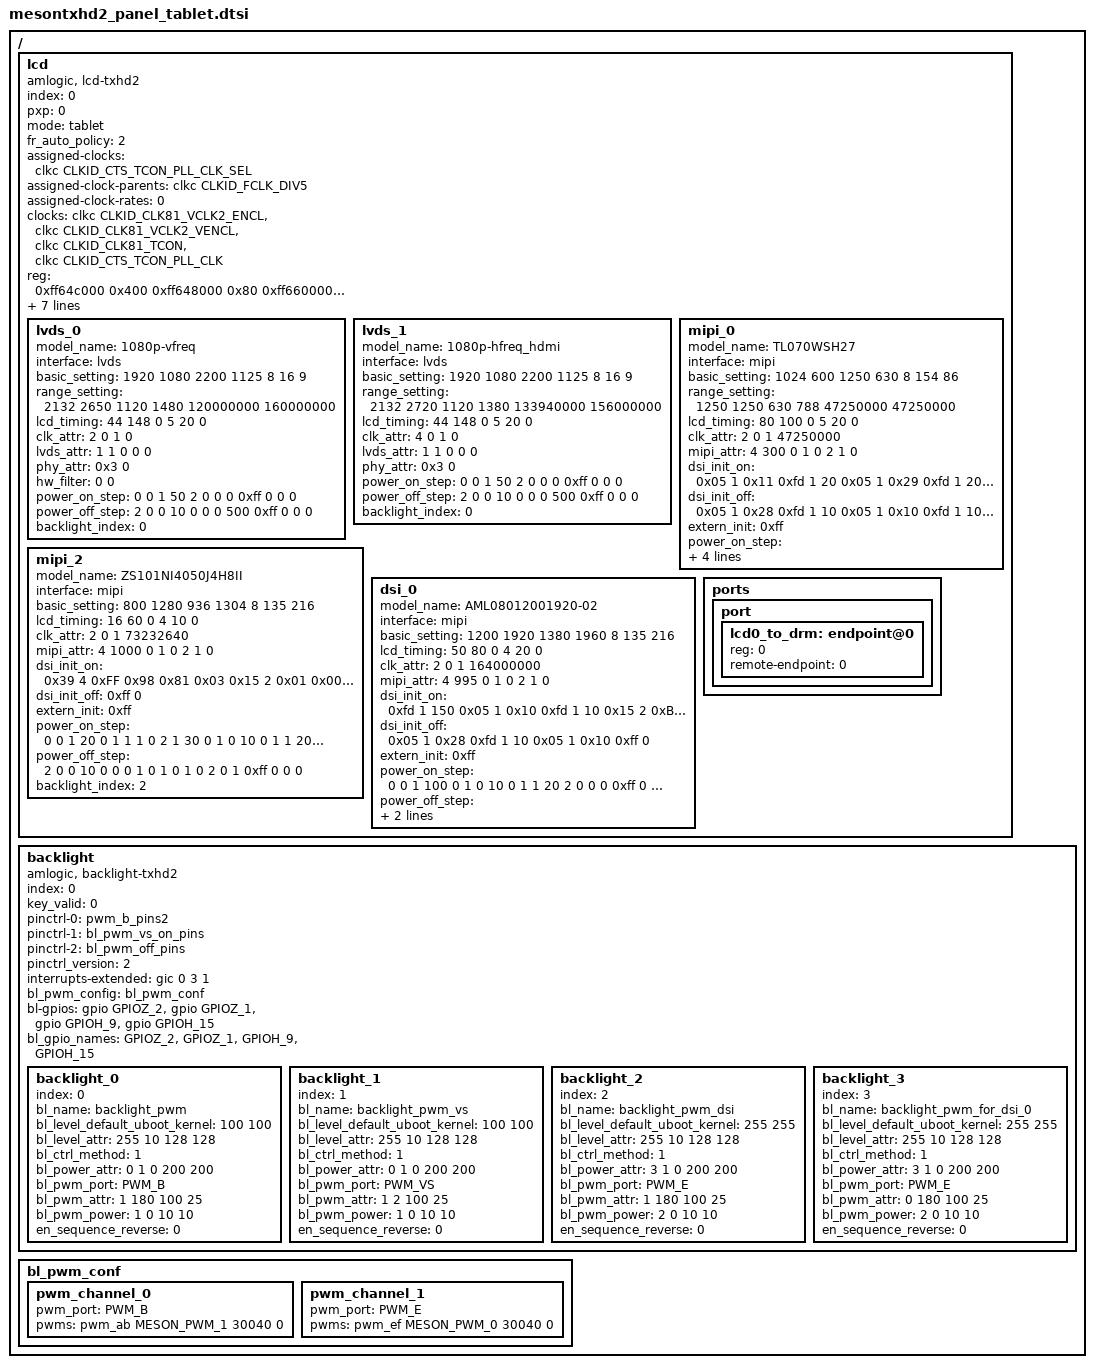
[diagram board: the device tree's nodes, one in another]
// SPDX-License-Identifier: (GPL-2.0+ OR MIT)
/*
 * Copyright (c) 2019 Amlogic, Inc. All rights reserved.
 */

/ {
	lcd:lcd {
		compatible = "amlogic, lcd-txhd2";
		status = "okay";
		index = <0>;
		pxp = <0>;
		mode = "tablet";
		fr_auto_policy = <2>; /* 0=disable, 1=enable */
		assigned-clocks = <&clkc CLKID_CTS_TCON_PLL_CLK_SEL>;
		assigned-clock-parents = <&clkc CLKID_FCLK_DIV5>;
		assigned-clock-rates = <0>;
		clocks = <&clkc CLKID_CLK81_VCLK2_ENCL>, <&clkc CLKID_CLK81_VCLK2_VENCL>,
			 <&clkc CLKID_CLK81_TCON>, <&clkc CLKID_CTS_TCON_PLL_CLK>;
		clock-names = "encl_top_gate", "encl_int_gate", "tcon_gate", "clk_tcon";
		reg = <0xff64c000 0x400    /* dsi_host */
			0xff648000 0x80    /* dsi_phy */
			0xff660000 0xd000  /* tcon */
			0xff634400 0x300   /* periphs */
			0xffd01000 0xa0    /* reset */
			0xff648000 0x100>; /* combo_dphy */
		interrupts = <0 3 1
			0 88 1>;
		interrupt-names = "vsync","tcon";

		lcd_cpu-gpios = <&gpio GPIOZ_3  GPIO_ACTIVE_HIGH
				 &gpio GPIOH_14 GPIO_ACTIVE_HIGH
				 &gpio GPIOH_10 GPIO_ACTIVE_HIGH>;
		lcd_cpu_gpio_names = "GPIOZ_3", "GPIOH_14", "GPIOH_10";

		config_check_glb = <1>;
		display_timing_req_min = <1  /*alert_level: 0:disable, 1:warning, 2:fatal error*/
			45   /*hsw+hbp*/
			0    /*hfp, 0 for no need*/
			20   /*vsw+vbp*/
			15>; /*vfp*/

		lvds_0{
			model_name = "1080p-vfreq";
			interface = "lvds"; /*lcd_interface(lvds, vbyone)*/
			basic_setting = <
				1920 1080 /*h_active, v_active*/
				2200 1125 /*h_period, v_period*/
				8      /*lcd_bits */
				16 9>; /*screen_widht, screen_height*/
			range_setting = <
				2132 2650  /*h_period_min,max*/
				1120 1480  /*v_period_min,max*/
				120000000 160000000>; /*pclk_min,max*/
			lcd_timing = <
				44 148 0  /*hs_width, hs_bp, hs_pol*/
				5  20 0>; /*vs_width, vs_bp, vs_pol*/
			clk_attr = <
				2 /*fr_adj_type: 0=clk, 1=htotal, 2=vtotal, 3=auto, 4=hdmi */
				0 /*clk_ss: [0:7]:level, [8:11]:freq, [12:15]: mode*/
				1 /*clk_auto_generate*/
				0>; /*pixel_clk(unit in Hz)*/
			lvds_attr = <
				1  /*lvds_repack*/
				1  /*dual_port*/
				0  /*pn_swap*/
				0  /*port_swap*/
				0>; /*lane_reverse*/
			phy_attr=<0x3 0>; /*vswing_level, preem_level*/
			hw_filter=<0 0>;  /* filter_time, filter_cnt*/

			/* power step: type, index, value, delay(ms) */
			power_on_step = <
				0 0 1 50   /*panel power*/
				2 0 0 0   /*signal enable*/
				0xff 0 0 0>; /*ending*/
			power_off_step = <
				2 0 0 10  /*signal disable*/
				0 0 0 500   /*panel power*/
				0xff 0 0 0>; /*ending*/
			backlight_index = <0>;
		};
		lvds_1{
			model_name = "1080p-hfreq_hdmi";
			interface = "lvds"; /*lcd_interface(lvds, vbyone)*/
			basic_setting = <
				1920 1080 /*h_active, v_active*/
				2200 1125 /*h_period, v_period*/
				8      /*lcd_bits*/
				16 9>; /*screen_widht, screen_height*/
			range_setting = <
				2132 2720 /*h_period min, max*/
				1120 1380 /*v_period min, max*/
				133940000 156000000>; /*pclk_min, max*/
			lcd_timing = <
				44 148 0   /*hs_width, hs_bp, hs_pol*/
				5  20  0>; /*vs_width, vs_bp, vs_pol*/
			clk_attr = <
				4 /*fr_adj_type: 0=clk, 1=htotal, 2=vtotal, 3=auto, 4=hdmi */
				0 /*clk_ss_level */
				1 /*clk_auto_generate*/
				0>; /*pixel_clk(unit in Hz)*/
			lvds_attr = <
				1 /*lvds_repack*/
				1 /*dual_port*/
				0 /*pn_swap*/
				0 /*port_swap*/
				0>; /*lane_reverse*/
			phy_attr=<0x3 0>; /*vswing_level, preem_level*/

			/* power step: type, index, value, delay(ms) */
			power_on_step = <
				0 0 1 50   /*panel power*/
				2 0 0 0   /*signal enable*/
				0xff 0 0 0>; /*ending*/
			power_off_step = <
				2 0 0 10  /*signal disable*/
				0 0 0 500   /*panel power*/
				0xff 0 0 0>; /*ending*/
			backlight_index = <0>;
		};

		mipi_0{
			model_name = "TL070WSH27";
			interface = "mipi";
			/*h_active, v_active, h_period, v_period, color_bit, width, height*/
			basic_setting = <1024 600 1250 630 8 154 86>;
			/* h_period(min, max) v_period(min, max) pclk(min, max) */
			range_setting = <1250 1250 630 788 47250000 47250000>;
			/*hs_width, hs_bp, hs_pol, vs_width, vs_bp, vs_pol*/
			lcd_timing = <80 100 0 5 20 0>;
			/* fr_adj_type(0=clk, 1=htotal, 2=vtotal), clk_ss_level, 1, pixel_clk */
			clk_attr = <2 0 1 47250000>; /*pixel_clk(unit in Hz)*/
			/* <lane, bit_rate, /, mode_init(0=video,1=cmd), mode_disp(0=video,1=cmd)*/
			/* video_mode(0=sync_pulse,1=sync_event,2=burst), clk_hs, />*/
			mipi_attr = <4 300 0 1 0 2 1 0>;

			/* dsi_init: data_type, num, data... */
			dsi_init_on = <0x05 1 0x11
					0xfd 1 20     /*delay(ms)*/
					0x05 1 0x29
					0xfd 1 20     /*delay(ms)*/
					0xff 0>; /*ending*/
			dsi_init_off = <0x05 1 0x28
					0xfd 1 10     /*delay(ms)*/
					0x05 1 0x10
					0xfd 1 10     /*delay(ms)*/
					0xff 0>; /*ending*/
			extern_init = <0xff>; /*0xff for invalid*/

			/* power step: type, index, value, delay(ms) */
			power_on_step = <
				0 0 1 100
				0 1 0 10
				0 1 1 20
				2 0 0 0
				0xff 0 0 0>; /*ending*/
			power_off_step = <
				2 0 0 50
				0 1 0 10
				0 0 0 100
				0xff 0 0 0>; /*ending*/
			backlight_index = <2>;
		};

		mipi_2{
			model_name = "ZS101NI4050J4H8II";
			interface = "mipi";
			/*h_active, v_active, h_period, v_period, color_bit, width, height*/
			basic_setting = <800 1280 936 1304 8 135 216>;
			/*hs_width, hs_bp, hs_pol, vs_width, vs_bp, vs_pol*/
			lcd_timing = <16 60 0 4 10 0>;
			/* fr_adj_type(0=clk, 1=htotal, 2=vtotal), clk_ss_level, 1, pixel_clk */
			clk_attr = <2 0 1 73232640>;
			/* <lane, bit_rate, /, mode_init(0=video,1=cmd), mode_disp(0=video,1=cmd)*/
			/* video_mode(0=sync_pulse,1=sync_event,2=burst), clk_hs, />*/
			mipi_attr = <4 1000 0 1 0 2 1 0>;

			/* dsi_init: data_type, num, data... */
			dsi_init_on = <
				0x39 4 0xFF 0x98 0x81 0x03
				0x15 2 0x01 0x00 0x15 2 0x02 0x00 0x15 2 0x03 0x53 0x15 2 0x04 0x53
				0x15 2 0x05 0x13 0x15 2 0x06 0x04 0x15 2 0x07 0x02 0x15 2 0x08 0x02
				0x15 2 0x09 0x00 0x15 2 0x0a 0x00 0x15 2 0x0b 0x00 0x15 2 0x0c 0x00
				0x15 2 0x0d 0x00 0x15 2 0x0e 0x00 0x15 2 0x0f 0x00 0x15 2 0x10 0x00
				0x15 2 0x11 0x00 0x15 2 0x12 0x00 0x15 2 0x13 0x00 0x15 2 0x14 0x00
				0x15 2 0x15 0x05 0x15 2 0x16 0x05 0x15 2 0x17 0x03 0x15 2 0x18 0x03
				0x15 2 0x19 0x00 0x15 2 0x1a 0x00 0x15 2 0x1b 0x00 0x15 2 0x1c 0x00
				0x15 2 0x1d 0x00 0x15 2 0x1e 0xc0 0x15 2 0x1f 0x00 0x15 2 0x20 0x02
				0x15 2 0x21 0x09 0x15 2 0x22 0x00 0x15 2 0x23 0x00 0x15 2 0x24 0x00
				0x15 2 0x25 0x00 0x15 2 0x26 0x00 0x15 2 0x27 0x00 0x15 2 0x28 0x55
				0x15 2 0x29 0x03 0x15 2 0x2a 0x00 0x15 2 0x2b 0x00 0x15 2 0x2c 0x00
				0x15 2 0x2d 0x00 0x15 2 0x2e 0x00 0x15 2 0x2f 0x00 0x15 2 0x30 0x00
				0x15 2 0x31 0x00 0x15 2 0x32 0x00 0x15 2 0x33 0x00 0x15 2 0x34 0x00
				0x15 2 0x35 0x00 0x15 2 0x36 0x00 0x15 2 0x37 0x00 0x15 2 0x38 0x3C
				0x15 2 0x39 0x00 0x15 2 0x3a 0x00 0x15 2 0x3b 0x00 0x15 2 0x3c 0x00
				0x15 2 0x3d 0x00 0x15 2 0x3e 0x00 0x15 2 0x3f 0x00 0x15 2 0x40 0x00
				0x15 2 0x41 0x00 0x15 2 0x42 0x00 0x15 2 0x43 0x00 0x15 2 0x44 0x00
				0x15 2 0x50 0x01 0x15 2 0x51 0x23 0x15 2 0x52 0x45 0x15 2 0x53 0x67
				0x15 2 0x54 0x89 0x15 2 0x55 0xab 0x15 2 0x56 0x01 0x15 2 0x57 0x23
				0x15 2 0x58 0x45 0x15 2 0x59 0x67 0x15 2 0x5a 0x89 0x15 2 0x5b 0xab
				0x15 2 0x5c 0xcd 0x15 2 0x5d 0xef 0x15 2 0x5e 0x01 0x15 2 0x5f 0x0A
				0x15 2 0x60 0x02 0x15 2 0x61 0x02 0x15 2 0x62 0x08 0x15 2 0x63 0x15
				0x15 2 0x64 0x14 0x15 2 0x65 0x02 0x15 2 0x66 0x11 0x15 2 0x67 0x10
				0x15 2 0x68 0x02 0x15 2 0x69 0x0F 0x15 2 0x6a 0x0E 0x15 2 0x6b 0x02
				0x15 2 0x6c 0x0D 0x15 2 0x6d 0x0C 0x15 2 0x6e 0x06 0x15 2 0x6f 0x02
				0x15 2 0x70 0x02 0x15 2 0x71 0x02 0x15 2 0x72 0x02 0x15 2 0x73 0x02
				0x15 2 0x74 0x02 0x15 2 0x75 0x0A 0x15 2 0x76 0x02 0x15 2 0x77 0x02
				0x15 2 0x78 0x06 0x15 2 0x79 0x15 0x15 2 0x7a 0x14 0x15 2 0x7b 0x02
				0x15 2 0x7c 0x10 0x15 2 0x7d 0x11 0x15 2 0x7e 0x02 0x15 2 0x7f 0x0C
				0x15 2 0x80 0x0D 0x15 2 0x81 0x02 0x15 2 0x82 0x0E 0x15 2 0x83 0x0F
				0x15 2 0x84 0x08 0x15 2 0x85 0x02 0x15 2 0x86 0x02 0x15 2 0x87 0x02
				0x15 2 0x88 0x02 0x15 2 0x89 0x02 0x15 2 0x8A 0x02
				0x39 4 0xFF 0x98 0x81 0x04
				0x15 2 0x3B 0xC0 0x15 2 0x6C 0x15 0x15 2 0x6E 0x30 0x15 2 0x6F 0x33
				0x15 2 0x8D 0x1F 0x15 2 0x3A 0x24 0x15 2 0x35 0x1F 0x15 2 0x87 0xBA
				0x15 2 0x26 0x76 0x15 2 0xB2 0xD1 0x15 2 0xB5 0x07 0x15 2 0x88 0x0B
				0x15 2 0x21 0x30
				0x39 4 0xFF 0x98 0x81 0x01
				0x15 2 0x22 0x0A 0x15 2 0x31 0x09 0x15 2 0x40 0x33 0x15 2 0x42 0x44
				0x15 2 0x53 0x2E 0x15 2 0x55 0x88 0x15 2 0x50 0x95 0x15 2 0x51 0x95
				0x15 2 0x60 0x43 0x15 2 0x2E 0xC8 0x15 2 0xA0 0x0F 0x15 2 0xA1 0x1D
				0x15 2 0xA2 0x2A 0x15 2 0xA3 0x14 0x15 2 0xA4 0x16 0x15 2 0xA5 0x29
				0x15 2 0xA6 0x1D 0x15 2 0xA7 0x1E 0x15 2 0xA8 0x83 0x15 2 0xA9 0x1E
				0x15 2 0xAA 0x2B 0x15 2 0xAB 0x6F 0x15 2 0xAC 0x18 0x15 2 0xAD 0x17
				0x15 2 0xAE 0x4C 0x15 2 0xAF 0x22 0x15 2 0xB0 0x27 0x15 2 0xB1 0x4D
				0x15 2 0xB2 0x5C 0x15 2 0xB3 0x2B 0x15 2 0xC0 0x0F 0x15 2 0xC1 0x1D
				0x15 2 0xC2 0x2A 0x15 2 0xC3 0x14 0x15 2 0xC4 0x16 0x15 2 0xC5 0x29
				0x15 2 0xC6 0x1D 0x15 2 0xC7 0x1E 0x15 2 0xC8 0x83 0x15 2 0xC9 0x1E
				0x15 2 0xCA 0x2B 0x15 2 0xCB 0x6F 0x15 2 0xCC 0x18 0x15 2 0xCD 0x17
				0x15 2 0xCE 0x4C 0x15 2 0xCF 0x22 0x15 2 0xD0 0x27 0x15 2 0xD1 0x4D
				0x15 2 0xD2 0x5C 0x15 2 0xD3 0x2B
				0x39 4 0xFF 0x98 0x81 0x00
				0x15 2 0x35 0x00
				0x05 1 0x11
				0xfd 1 120
				0x05 1 0x29
				0xfd 1 20
				0xff 0>; /*ending*/
			dsi_init_off = <0xff 0>; /*ending*/
			extern_init = <0xff>; /*0xff for invalid*/

			/* power step: type, index, value, delay(ms) */
			power_on_step = <
				0 0 1 20
				0 1 1 1
				0 2 1 30
				0 1 0 10
				0 1 1 20
				2 0 0 0
				0xff 0 0 0>; /*ending*/
			power_off_step = <
				2 0 0 10
				0 0 0 1
				0 1 0 1
				0 2 0 1
				0xff 0 0 0>; /*ending*/
			backlight_index = <2>;
		};
		dsi_0{
			model_name = "AML08012001920-02";
			interface = "mipi";
			/*h_active, v_active, h_period, v_period, color_bit, width, height*/
			basic_setting = <1200 1920 1380 1960 8 135 216>;
			/*hs_width, hs_bp, hs_pol, vs_width, vs_bp, vs_pol*/
			lcd_timing = <50 80 0 4 20 0>;
			/* fr_adj_type(0=clk, 1=htotal, 2=vtotal), clk_ss_level, 1, pixel_clk */
			clk_attr = <2 0 1 164000000>;
			/* <lane, bit_rate, /, mode_init(0=video,1=cmd), mode_disp(0=video,1=cmd)*/
			/* video_mode(0=sync_pulse,1=sync_event,2=burst), clk_hs, />*/
			mipi_attr = <4 995 0 1 0 2 1 0>;
			/* dsi_init: data_type, num, data... */
			dsi_init_on = <
				0xfd 1 150
				0x05 1 0x10
				0xfd 1 10
				0x15 2 0xB0 0x05 0x15 2 0xB3 0x52 0x15 2 0xB0 0x01 0x15 2 0xC8 0x00
				0x15 2 0xC9 0x00 0x15 2 0xCC 0x26 0x15 2 0xCD 0x26 0x15 2 0xDC 0x00
				0x15 2 0xDD 0x00 0x15 2 0xE0 0x26 0x15 2 0xE1 0x26 0x15 2 0xB0 0x03
				0x15 2 0xC3 0x2A 0x15 2 0xE7 0x2A 0x15 2 0xC5 0x2A 0x15 2 0xDE 0x2A
				0x15 2 0xB0 0x00 0x15 2 0xB6 0x03 0x15 2 0xBA 0x87 0x15 2 0xBD 0x78
				0x15 2 0xBF 0x15 0x15 2 0xC0 0x12 0x15 2 0xC2 0x0C 0x15 2 0xC3 0x02
				0x15 2 0xC4 0x0C 0x15 2 0xC5 0x02 0x15 2 0xB0 0x06 0x15 2 0xC0 0xA5
				0x15 2 0xD5 0x20 0x15 2 0xC0 0x00
				0x15 2 0xB0 0x02 /* page2 */
				0x15 2 0xC0 0x00 0x15 2 0xC1 0x02 0x15 2 0xC2 0x06 0x15 2 0xC3 0x16
				0x15 2 0xC4 0x0E 0x15 2 0xC5 0x18 0x15 2 0xC6 0x26 0x15 2 0xC7 0x32
				0x15 2 0xC8 0x3F 0x15 2 0xC9 0x3F 0x15 2 0xCA 0x3F 0x15 2 0xCB 0x3F
				0x15 2 0xCC 0x3D 0x15 2 0xCD 0x2F 0x15 2 0xCE 0x2F 0x15 2 0xCF 0x2F
				0x15 2 0xD0 0x07 0x15 2 0xD2 0x00 0x15 2 0xD3 0x02 0x15 2 0xD4 0x06
				0x15 2 0xD5 0x12 0x15 2 0xD6 0x0A 0x15 2 0xD7 0x14 0x15 2 0xD8 0x22
				0x15 2 0xD9 0x2E 0x15 2 0xDA 0x3D 0x15 2 0xDB 0x3F 0x15 2 0xDC 0x3F
				0x15 2 0xDD 0x3F 0x15 2 0xDE 0x3D 0x15 2 0xDF 0x2F 0x15 2 0xE0 0x2F
				0x15 2 0xE1 0x2F 0x15 2 0xE2 0x07
				0x15 2 0xB0 0x07 /* page7 */
				0x15 2 0xB1 0x00 0x15 2 0xB2 0x19 0x15 2 0xB3 0x31 0x15 2 0xB4 0x5A
				0x15 2 0xB5 0x7C 0x15 2 0xB6 0x9C 0x15 2 0xB7 0xD3 0x15 2 0xB8 0x0E
				0x15 2 0xB9 0x7D 0x15 2 0xBA 0xE0 0x15 2 0xBB 0x7A 0x15 2 0xBC 0xE6
				0x15 2 0xBD 0xE9 0x15 2 0xBE 0x41 0x15 2 0xBF 0x91 0x15 2 0xC0 0xB0
				0x15 2 0xC1 0xCF 0x15 2 0xC2 0xDC 0x15 2 0xC3 0xE9 0x15 2 0xC4 0xEF
				0x15 2 0xC5 0xF5 0x15 2 0xC6 0xFA 0x15 2 0xC7 0xFB 0x15 2 0xC8 0xFC
				0x15 2 0xC9 0x00 0x15 2 0xCA 0x01 0x15 2 0xCB 0x5A 0x15 2 0xCC 0xBF
				0x15 2 0xCD 0xFF 0x15 2 0xCE 0xFF
				0x15 2 0xB0 0x08 /* page8 */
				0x15 2 0xB1 0x00 0x15 2 0xB2 0x19 0x15 2 0xB3 0x31 0x15 2 0xB4 0x5A
				0x15 2 0xB5 0x7C 0x15 2 0xB6 0x9C 0x15 2 0xB7 0xD3 0x15 2 0xB8 0x0E
				0x15 2 0xB9 0x7D 0x15 2 0xBA 0xE0 0x15 2 0xBB 0x7A 0x15 2 0xBC 0xE6
				0x15 2 0xBD 0xE9 0x15 2 0xBE 0x41 0x15 2 0xBF 0x91 0x15 2 0xC0 0xB0
				0x15 2 0xC1 0xCF 0x15 2 0xC2 0xDC 0x15 2 0xC3 0xE9 0x15 2 0xC4 0xEF
				0x15 2 0xC5 0xF5 0x15 2 0xC6 0xFA 0x15 2 0xC7 0xFB 0x15 2 0xC8 0xFC
				0x15 2 0xC9 0x00 0x15 2 0xCA 0x01 0x15 2 0xCB 0x5A 0x15 2 0xCC 0xBF
				0x15 2 0xCD 0xFF 0x15 2 0xCE 0xFF
				0x15 2 0xB0 0x09 /* page9 */
				0x15 2 0xB1 0x00 0x15 2 0xB2 0x19 0x15 2 0xB3 0x31 0x15 2 0xB4 0x5A
				0x15 2 0xB5 0x7C 0x15 2 0xB6 0x9C 0x15 2 0xB7 0xD3 0x15 2 0xB8 0x0E
				0x15 2 0xB9 0x7D 0x15 2 0xBA 0xE0 0x15 2 0xBB 0x7A 0x15 2 0xBC 0xE6
				0x15 2 0xBD 0xE9 0x15 2 0xBE 0x41 0x15 2 0xBF 0x91 0x15 2 0xC0 0xB0
				0x15 2 0xC1 0xCF 0x15 2 0xC2 0xDC 0x15 2 0xC3 0xE9 0x15 2 0xC4 0xEF
				0x15 2 0xC5 0xF5 0x15 2 0xC6 0xFA 0x15 2 0xC7 0xFB 0x15 2 0xC8 0xFC
				0x15 2 0xC9 0x00 0x15 2 0xCA 0x01 0x15 2 0xCB 0x5A 0x15 2 0xCC 0xBF
				0x15 2 0xCD 0xFF 0x15 2 0xCE 0xFF
				0x15 2 0xB0 0x0A /* page10 */
				0x15 2 0xB1 0x00 0x15 2 0xB2 0x19 0x15 2 0xB3 0x31 0x15 2 0xB4 0x5A
				0x15 2 0xB5 0x7C 0x15 2 0xB6 0x9C 0x15 2 0xB7 0xD3 0x15 2 0xB8 0x0E
				0x15 2 0xB9 0x7D 0x15 2 0xBA 0xE0 0x15 2 0xBB 0x7A 0x15 2 0xBC 0xE6
				0x15 2 0xBD 0xE9 0x15 2 0xBE 0x41 0x15 2 0xBF 0x91 0x15 2 0xC0 0xB0
				0x15 2 0xC1 0xCF 0x15 2 0xC2 0xDC 0x15 2 0xC3 0xE9 0x15 2 0xC4 0xEF
				0x15 2 0xC5 0xF5 0x15 2 0xC6 0xFA 0x15 2 0xC7 0xFC 0x15 2 0xC8 0xFC
				0x15 2 0xC9 0x00 0x15 2 0xCA 0x01 0x15 2 0xCB 0x5A 0x15 2 0xCC 0xBF
				0x15 2 0xCD 0xFF 0x15 2 0xCE 0xFF
				0x15 2 0xB0 0x0B /* page11 */
				0x15 2 0xB1 0x00 0x15 2 0xB2 0x19 0x15 2 0xB3 0x31 0x15 2 0xB4 0x5A
				0x15 2 0xB5 0x7C 0x15 2 0xB6 0x9C 0x15 2 0xB7 0xD3 0x15 2 0xB8 0x0E
				0x15 2 0xB9 0x7D 0x15 2 0xBA 0xE0 0x15 2 0xBB 0x7A 0x15 2 0xBC 0xE6
				0x15 2 0xBD 0xE9 0x15 2 0xBE 0x41 0x15 2 0xBF 0x91 0x15 2 0xC0 0xB0
				0x15 2 0xC1 0xCF 0x15 2 0xC2 0xDC 0x15 2 0xC3 0xE9 0x15 2 0xC4 0xEF
				0x15 2 0xC5 0xF5 0x15 2 0xC6 0xFA 0x15 2 0xC7 0xFC 0x15 2 0xC8 0xFC
				0x15 2 0xC9 0x00 0x15 2 0xCA 0x01 0x15 2 0xCB 0x5A 0x15 2 0xCC 0xBF
				0x15 2 0xCD 0xFF 0x15 2 0xCE 0xFF
				0x15 2 0xB0 0x0C /* page12 */
				0x15 2 0xB1 0x00 0x15 2 0xB2 0x19 0x15 2 0xB3 0x31 0x15 2 0xB4 0x5A
				0x15 2 0xB5 0x7C 0x15 2 0xB6 0x9C 0x15 2 0xB7 0xD3 0x15 2 0xB8 0x0E
				0x15 2 0xB9 0x7D 0x15 2 0xBA 0xE0 0x15 2 0xBB 0x7A 0x15 2 0xBC 0xE6
				0x15 2 0xBD 0xE9 0x15 2 0xBE 0x41 0x15 2 0xBF 0x91 0x15 2 0xC0 0xB0
				0x15 2 0xC1 0xCF 0x15 2 0xC2 0xDC 0x15 2 0xC3 0xE9 0x15 2 0xC4 0xEF
				0x15 2 0xC5 0xF5 0x15 2 0xC6 0xFA 0x15 2 0xC7 0xFC 0x15 2 0xC8 0xFC
				0x15 2 0xC9 0x00 0x15 2 0xCA 0x01 0x15 2 0xCB 0x5A 0x15 2 0xCC 0xBF
				0x15 2 0xCD 0xFF 0x15 2 0xCE 0xFF
				0xfd 1 10
				0x05 1 0x11
				0xfd 1 100
				0x05 1 0x29
				0xfd 1 50
				0xff 0>; /*ending*/
			dsi_init_off = <
				0x05 1 0x28
				0xfd 1 10
				0x05 1 0x10
				0xff 0>;
			extern_init = <0xff>; /*0xff for invalid*/

			/* power step: type, index, value, delay(ms) */
			power_on_step = <
				0 0 1 100
				0 1 0 10
				0 1 1 20
				2 0 0 0
				0xff 0 0 0>; /*ending*/
			power_off_step = <
				2 0 0 50
				0 1 0 10
				0 0 0 100
				0xff 0 0 0>; /*ending*/
			backlight_index = <0x3>;
		};
		ports {
			port {
				#address-cells = <1>;
				#size-cells = <0>;
				lcd0_to_drm: endpoint@0 {
					reg = <0>;
					remote-endpoint = <0>;
				};
			};
		};
	};

	backlight{
		compatible = "amlogic, backlight-txhd2";
		status = "okay";
		index = <0>;
		key_valid = <0>;
		pinctrl-names = "pwm_on","pwm_vs_on",
				"pwm_off";
		pinctrl-0 = <&pwm_b_pins2>;
		pinctrl-1 = <&bl_pwm_vs_on_pins>;
		pinctrl-2 = <&bl_pwm_off_pins>;
		pinctrl_version = <2>; /* for uboot */
		interrupts-extended = <&gic 0 3 1>;
		interrupt-names = "vsync";
		bl_pwm_config = <&bl_pwm_conf>;

		/* pwm port: PWM_A, PWM_B, PWM_C, PWM_D, PWM_E, PWM_F, PWM_VS*/
		/* power index:(point gpios_index, 0xff=invalid) */
		/* power value:(0=output low, 1=output high, 2=input) */
		/* power delay:(unit in ms) */
		bl-gpios = <&gpio GPIOZ_2 GPIO_ACTIVE_HIGH
			&gpio GPIOZ_1 GPIO_ACTIVE_HIGH
			&gpio GPIOH_9 GPIO_ACTIVE_HIGH
			&gpio GPIOH_15 GPIO_ACTIVE_HIGH>;
		bl_gpio_names = "GPIOZ_2", "GPIOZ_1", "GPIOH_9", "GPIOH_15";

		backlight_0{
			index = <0>;
			bl_name = "backlight_pwm";
			bl_level_default_uboot_kernel = <100 100>;
			bl_level_attr = <255 10 /*max, min*/
				128 128>; /*mid, mid_mapping*/
			bl_ctrl_method = <1>; /*1=pwm,2=pwm_combo,3=ldim*/
			bl_power_attr = <0 /*en_gpio_index*/
				1 0 /*on_value, off_value*/
				200 200>; /*on_delay(ms), off_delay(ms)*/
			bl_pwm_port = "PWM_B";
			bl_pwm_attr = <1 /*pwm_method(0=negative, 1=positive)*/
				180 /*pwm_freq(pwm:Hz, pwm_vs:multiple of vs)*/
				100 25>; /*duty_max(%), duty_min(%)*/
			bl_pwm_power = <1 0 /*pwm_gpio_index, pwm_gpio_off*/
				10 10>; /*pwm_on_delay(ms), pwm_off_delay(ms)*/
			en_sequence_reverse = <0>; /* 1 for reverse */
		};
		backlight_1{
			index = <1>;
			bl_name = "backlight_pwm_vs";
			bl_level_default_uboot_kernel = <100 100>;
			bl_level_attr = <255 10 /*max, min*/
				128 128>; /*mid, mid_mapping*/
			bl_ctrl_method = <1>; /*1=pwm,2=pwm_combo,3=ldim*/
			bl_power_attr = <0  /*en_gpio_index*/
				1 0 /*on_value, off_value*/
				200 200>; /* on_delay(ms), off_delay(ms)*/
			bl_pwm_port = "PWM_VS";
			bl_pwm_attr = <1 /*pwm_method(0=negative, 1=positive)*/
				2 /*pwm_freq(pwm:Hz, pwm_vs:multiple of vs)*/
				100 25>; /*duty_max(%), duty_min(%)*/
			bl_pwm_power = <1 0 /*pwm_gpio_index, pwm_gpio_off*/
				10 10>; /*pwm_on_delay(ms), pwm_off_delay(ms)*/
			en_sequence_reverse = <0>; /* 1 for reverse */
		};
		backlight_2{
			index = <2>;
			bl_name = "backlight_pwm_dsi";
			bl_level_default_uboot_kernel = <255 255>;
			bl_level_attr = <255 10 /*max, min*/
				128 128>; /*mid, mid_mapping*/
			bl_ctrl_method = <1>; /*1=pwm,2=pwm_combo,3=ldim*/
			bl_power_attr = <3 /*en_gpio_index*/
				1 0 /*on_value, off_value*/
				200 200>; /*on_delay(ms), off_delay(ms)*/
			bl_pwm_port = "PWM_E";
			bl_pwm_attr = <1 /*pwm_method(0=negative, 1=positive)*/
				180 /*pwm_freq(pwm:Hz, pwm_vs:multiple of vs)*/
				100 25>; /*duty_max(%), duty_min(%)*/
			bl_pwm_power = <2 0 /*pwm_gpio_index, pwm_gpio_off*/
				10 10>; /*pwm_on_delay(ms), pwm_off_delay(ms)*/
			en_sequence_reverse = <0>; /* 1 for reverse */
		};
		backlight_3{
			index = <3>;
			bl_name = "backlight_pwm_for_dsi_0";
			bl_level_default_uboot_kernel = <255 255>;
			bl_level_attr = <255 10 /*max, min*/
				128 128>; /*mid, mid_mapping*/
			bl_ctrl_method = <1>; /*1=pwm,2=pwm_combo,3=ldim*/
			bl_power_attr = <3 /*en_gpio_index*/
				1 0 /*on_value, off_value*/
				200 200>; /*on_delay(ms), off_delay(ms)*/
			bl_pwm_port = "PWM_E";
			bl_pwm_attr = <0 /*pwm_method(0=negative, 1=positive)*/
				180 /*pwm_freq(pwm:Hz, pwm_vs:multiple of vs)*/
				100 25>; /*duty_max(%), duty_min(%)*/
			bl_pwm_power = <2 0 /*pwm_gpio_index, pwm_gpio_off*/
				10 10>; /*pwm_on_delay(ms), pwm_off_delay(ms)*/
			en_sequence_reverse = <0>; /* 1 for reverse */
		};
	};

	bl_pwm_conf:bl_pwm_conf{
		pwm_channel_0 {
			pwm_port = "PWM_B";
			pwms = <&pwm_ab MESON_PWM_1 30040 0>;
		};
		pwm_channel_1 {
			pwm_port = "PWM_E";
			pwms = <&pwm_ef MESON_PWM_0 30040 0>;
		};
	};
};
